# AT32F423 register map
Vendor: Keil; Series: AT32F423; File version: 1.0
CPU: CM4 r0p1, little endian, no MPU, FPU, 4 interrupt priority bits
Registers are 32-bit, read-write, reset 0x0 unless marked. A register's access mark holds for its fields unless they carry their own. Offsets are from the block's base; [hi:lo] are bit positions; {n}, {i} and the like mark numbered series.

## GPIOA — General purpose I/Os
Base 0x40020000
Same registers: GPIOB 0x40020400, GPIOC 0x40020800, GPIOD 0x40020C00, GPIOE 0x40021000, GPIOF 0x40021400
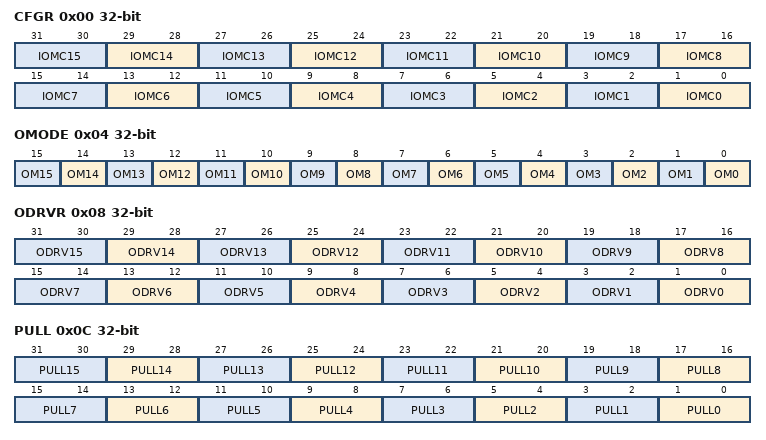
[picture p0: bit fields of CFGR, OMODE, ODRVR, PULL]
0x00 CFGR — GPIO function configurate register. **WARNING**: `reset()` writes the hardware reset value which does NOT account for SWD/JTAG pin default configuration. Calling `reset()` may disable debug access to the MCU.
  [2n+1:2n] IOMC{n} (n=0..15) — GPIOx pin {n} mode configurate
    0=Input mode; 1=Output (General-purpose output mode); 2=Multiplexed function mode; 3=Analog mode
0x04 OMODE — GPIO output mode register
  [n] OM{n} (n=0..15) — GPIOx pin {n} output mode configurate
    0=PushPull; 1=OpenDrain
0x08 ODRVR — GPIO drive capability register
  [2n+1:2n] ODRV{n} (n=0..15) — GPIOx pin {n} output drive capability
    1=Large sourcing/sinking strength; other=Normal sourcing/sinking strength
0x0C PULL — GPIO pull-up/pull-down register. **WARNING**: `reset()` writes the hardware reset value which does NOT account for SWD/JTAG pin default configuration. Calling `reset()` may disable debug access to the MCU.
  [2n+1:2n] PULL{n} (n=0..15) — GPIOx pin {n} pull configuration
    0=No pull-up/pull-down; 1=PullUp; 2=PullDown
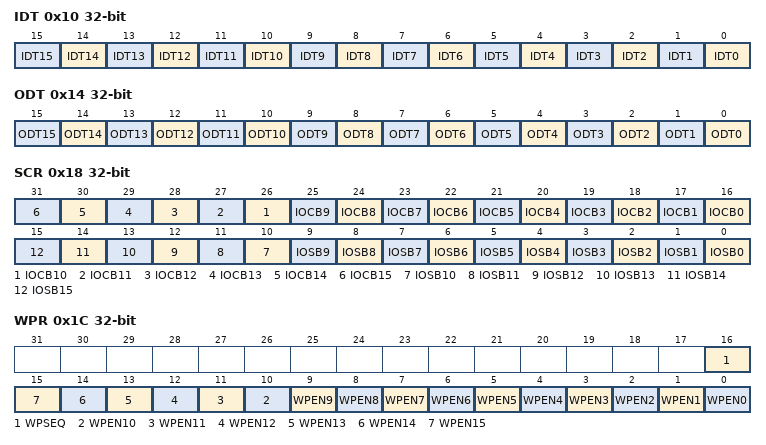
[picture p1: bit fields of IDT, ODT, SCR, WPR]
0x10 IDT ro — GPIO input data register
  [n] IDT{n} (n=0..15) — Port input data
    0=Low (Input is logic low); 1=High (Input is logic high)
0x14 ODT — GPIO output data register
  [n] ODT{n} (n=0..15) — Port output data
    on read: 0=PullDown; 1=PullUp | on write: 0=Low (Set output to logic low); 1=High (Set output to logic high)
0x18 SCR wo — Port bit set/clear register
  [n+16] IOCB{n} (n=0..15) write-1-clears — Clear bit {n}
    1=Clear the corresponding ODT bit
  [n] IOSB{n} (n=0..15) write-1-sets — Set bit {n}
    1=Set (Set the corresponding ODT bit)
0x1C WPR — Port write protect register
  [16] WPSEQ — Write protect sequence
    0=Clear; 1=Set
  [n] WPEN{n} (n=0..15) — Write protect enable {n}
    on read: 0=NotProtected (Port is not write protected); 1=Protected (Port is write protected) | on write: 0=NoProtect (No effect); 1=Protect (Write protect)
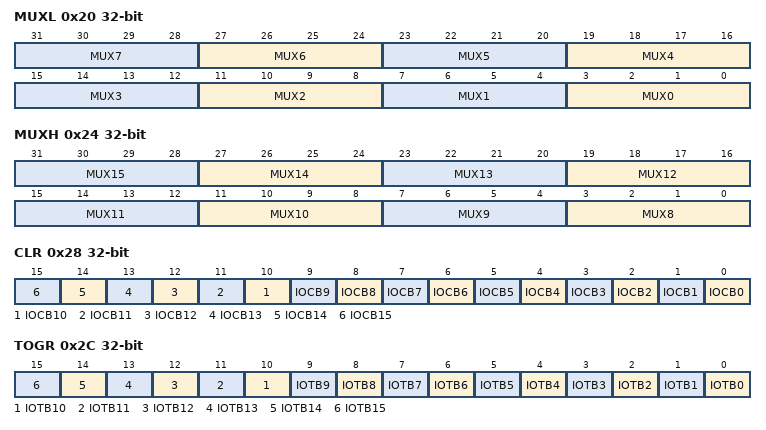
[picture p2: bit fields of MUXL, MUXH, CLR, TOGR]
0x20 MUXL — GPIO muxing function low register
  [4n+3:4n] MUX{n} (n=0..7) — GPIOx pin {n} muxing
0x24 MUXH — GPIO muxing function high register
  [4n-29:4n-32] MUX{n} (n=8..15) — GPIOx pin {n} muxing
0x28 CLR wo — GPIO bit reset register
  [n] IOCB{n} (n=0..15) write-1-clears — Clear bit {n}
    1=Clear the corresponding ODT bit
0x2C TOGR wo — GPIO bit toggle register
  [n] IOTB{n} (n=0..15) — Toggle bit {n}
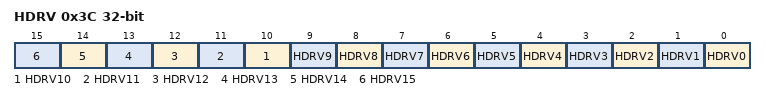
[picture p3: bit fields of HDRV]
0x3C HDRV — Huge current driver
  [n] HDRV{n} (n=0..15) — Port x driver bit y
    0=Normal/large drive strength (according to ODRVR); 1=Huge (GPIO is configured as maximum sourcing/sinking strength)

## EXINT
Base 0x40013C00
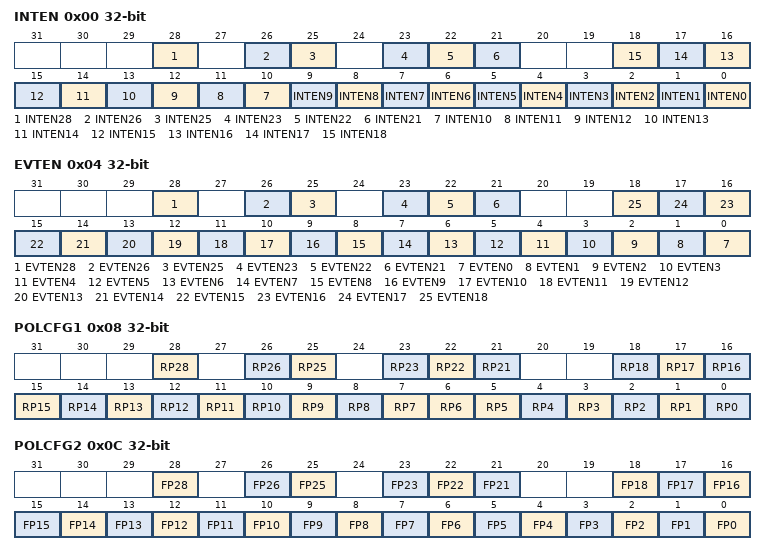
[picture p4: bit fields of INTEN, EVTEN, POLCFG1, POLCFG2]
0x00 INTEN — Interrupt enable register
  [28] INTEN28 — Interrupt enable or disable on line 28
  [26] INTEN26 — Interrupt enable or disable on line 26
  [25] INTEN25 — Interrupt enable or disable on line 25
  [23] INTEN23 — Interrupt enable or disable on line 23
  [22] INTEN22 — Interrupt enable or disable on line 22
  [21] INTEN21 — Interrupt enable or disable on line 21
  [n] INTEN{n} (n=0..18) — Interrupt enable or disable on line {n}
0x04 EVTEN — Event enable register
  [28] EVTEN28 — Event enable or disable on line 28
  [26] EVTEN26 — Event enable or disable on line 26
  [25] EVTEN25 — Event enable or disable on line 25
  [23] EVTEN23 — Event enable or disable on line 23
  [22] EVTEN22 — Event enable or disable on line 22
  [21] EVTEN21 — Event enable or disable on line 21
  [n] EVTEN{n} (n=0..18) — Event enable or disable on line {n}
0x08 POLCFG1 — Rising polarity configuration register
  [28] RP28 — Rising polarity configuration bit of line 28
  [26] RP26 — Rising polarity configuration bit of line 26
  [25] RP25 — Rising polarity configuration bit of line 25
  [23] RP23 — Rising polarity configuration bit of line 23
  [22] RP22 — Rising polarity configuration bit of line 22
  [21] RP21 — Rising polarity configuration bit of line 21
  [n] RP{n} (n=7..18) — Rising polarity configuration bit of line {n}
  [6] RP6 — Rising polarity configuration bit of linee 6
  [n] RP{n} (n=0..5) — Rising polarity configuration bit of line {n}
0x0C POLCFG2 — Falling polarity configuration register
  [28] FP28 — Falling polarity event configuration bit of line 28
  [26] FP26 — Falling polarity event configuration bit of line 26
  [25] FP25 — Falling polarity event configuration bit of line 25
  [23] FP23 — Falling polarity event configuration bit of line 23
  [22] FP22 — Falling polarity event configuration bit of line 22
  [21] FP21 — Falling polarity event configuration bit of line 21
  [n] FP{n} (n=0..18) — Falling polarity event configuration bit of line {n}
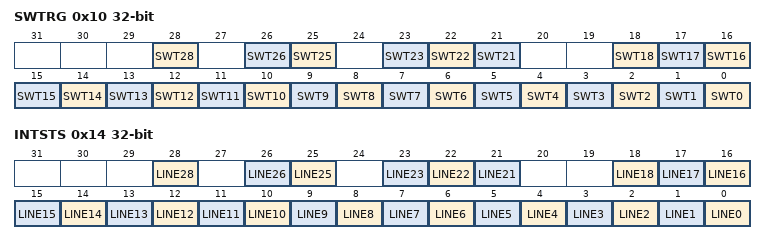
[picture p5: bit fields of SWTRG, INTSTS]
0x10 SWTRG — Software triggle register
  [28] SWT28 — Software triggle on line 28
  [26] SWT26 — Software triggle on line 26
  [25] SWT25 — Software triggle on line 25
  [23] SWT23 — Software triggle on line 23
  [22] SWT22 — Software triggle on line 22
  [21] SWT21 — Software triggle on line 21
  [n] SWT{n} (n=0..18) — Software triggle on line {n}
0x14 INTSTS — Interrupt status register
  [28] LINE28 — Line 28 state bit
  [26] LINE26 — Line 26 state bit
  [25] LINE25 — Line 25 state bit
  [23] LINE23 — Line 23 state bit
  [22] LINE22 — Line 22 state bit
  [21] LINE21 — Line 21 state bit
  [n] LINE{n} (n=0..18) — Line {n} state bit
